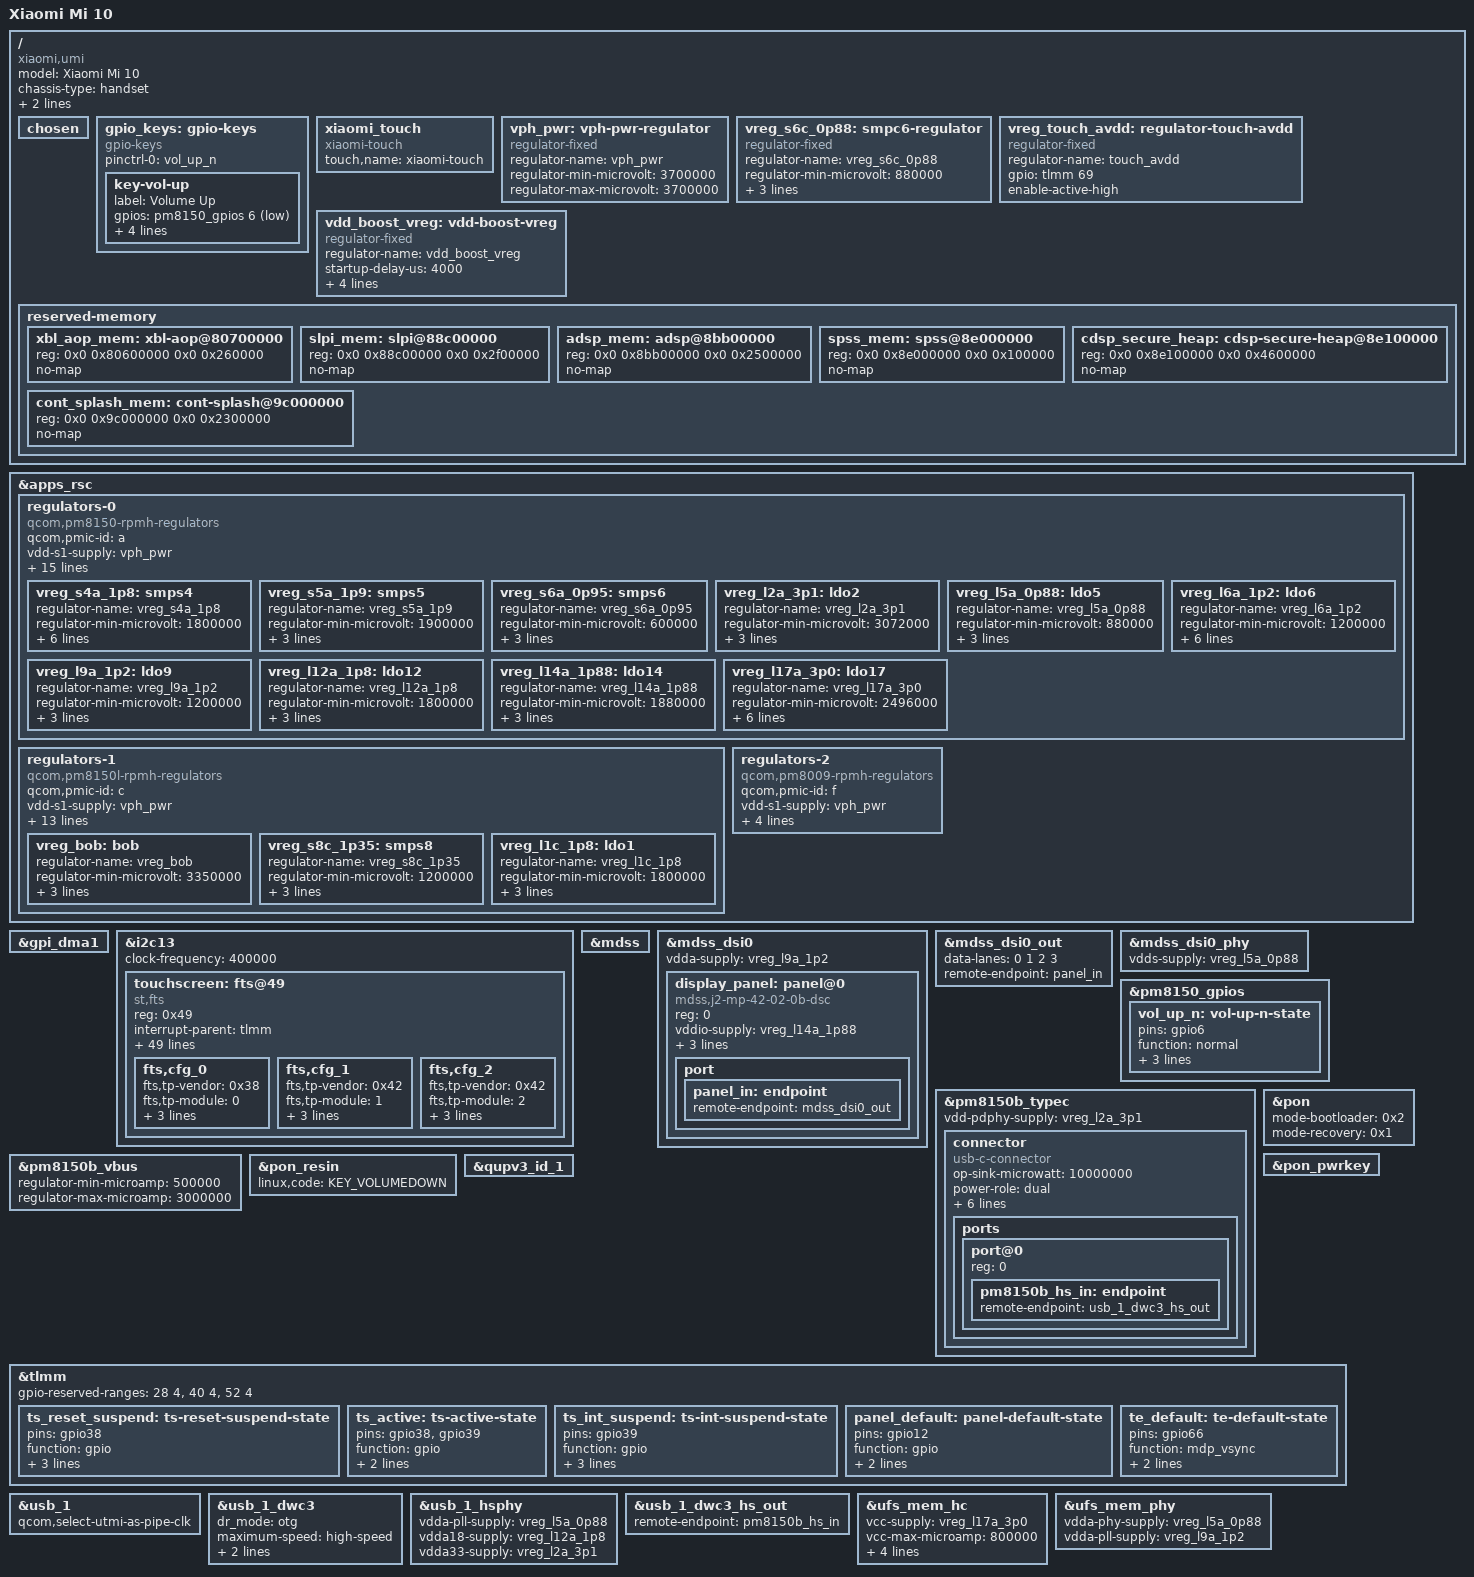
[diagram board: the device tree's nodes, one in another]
// SPDX-License-Identifier: GPL-2.0-only OR BSD-2-Clause
/*
 * Copyright (c) 2025 Xilin Wu <wuxilin123@gmail.com>
 */

/dts-v1/;

#include <dt-bindings/arm/qcom,ids.h>
#include <dt-bindings/phy/phy.h>
#include <dt-bindings/regulator/qcom,rpmh-regulator.h>
#include <dt-bindings/usb/pd.h>
#include "sm8250.dtsi"
#include "pm8150.dtsi"
#include "pm8150b.dtsi"
#include "pm8150l.dtsi"
#include "pm8009.dtsi"

/*
 * Delete following upstream (sm8250.dtsi) reserved
 * memory mappings which are different on this device.
 */
/delete-node/ &adsp_mem;
/delete-node/ &cdsp_secure_heap;
/delete-node/ &slpi_mem;
/delete-node/ &spss_mem;
/delete-node/ &xbl_aop_mem;

/ {

	model = "Xiaomi Mi 10";
	compatible = "xiaomi,umi", "qcom,sm8250";

	chassis-type = "handset";

	/* required for bootloader to select correct board */
	qcom,msm-id = <QCOM_ID_SM8250 0x20001>; /* SM8250 v2.1 */
	qcom,board-id = <0x2b 0>;

	chosen {
		#address-cells = <2>;
		#size-cells = <2>;
		ranges;

		// framebuffer: framebuffer@9c000000 {
		// 	compatible = "simple-framebuffer";
		// 	reg = <0x0 0x9c000000 0x0 0x2300000>;
		// 	width = <1080>;
		// 	height = <2340>;
		// 	stride = <(1080 * 4)>;
		// 	format = "a8r8g8b8";
		// 	clocks = <&gcc GCC_DISP_HF_AXI_CLK>,
		// 		 <&gcc GCC_DISP_SF_AXI_CLK>;
		// };
	};

	gpio_keys: gpio-keys {
		compatible = "gpio-keys";

		pinctrl-0 = <&vol_up_n>;
		pinctrl-names = "default";

		key-vol-up {
			label = "Volume Up";
			gpios = <&pm8150_gpios 6 GPIO_ACTIVE_LOW>;
			linux,code = <KEY_VOLUMEUP>;
			debounce-interval = <15>;
			linux,can-disable;
			wakeup-source;
		};
	};

	xiaomi_touch {
		compatible = "xiaomi-touch";
		touch,name = "xiaomi-touch";
	};

	vph_pwr: vph-pwr-regulator {
		compatible = "regulator-fixed";
		regulator-name = "vph_pwr";
		regulator-min-microvolt = <3700000>;
		regulator-max-microvolt = <3700000>;
	};

	/* S6c is really ebi.lvl but it's there for supply map completeness sake. */
	vreg_s6c_0p88: smpc6-regulator {
		compatible = "regulator-fixed";
		regulator-name = "vreg_s6c_0p88";
		regulator-min-microvolt = <880000>;
		regulator-max-microvolt = <880000>;
		regulator-always-on;
		vin-supply = <&vph_pwr>;
	};

	vreg_touch_avdd: regulator-touch-avdd {
		compatible = "regulator-fixed";
		regulator-name = "touch_avdd";
		gpio = <&tlmm 69 GPIO_ACTIVE_HIGH>;
		// startup-delay-us = <4000>;
		enable-active-high;
		// regulator-boot-on;
	};

	vdd_boost_vreg: vdd-boost-vreg {
		compatible = "regulator-fixed";
		regulator-name = "vdd_boost_vreg";
		startup-delay-us = <4000>;
		enable-active-high;
		regulator-always-on;
		regulator-boot-on;
		gpio = <&pm8150b_gpios 5 0>;
	};

	reserved-memory {
		xbl_aop_mem: xbl-aop@80700000 {
			reg = <0x0 0x80600000 0x0 0x260000>;
			no-map;
		};

		slpi_mem: slpi@88c00000 {
			reg = <0x0 0x88c00000 0x0 0x2f00000>;
			no-map;
		};

		adsp_mem: adsp@8bb00000 {
			reg = <0x0 0x8bb00000 0x0 0x2500000>;
			no-map;
		};

		spss_mem: spss@8e000000 {
			reg = <0x0 0x8e000000 0x0 0x100000>;
			no-map;
		};

		cdsp_secure_heap: cdsp-secure-heap@8e100000 {
			reg = <0x0 0x8e100000 0x0 0x4600000>;
			no-map;
		};

		cont_splash_mem: cont-splash@9c000000 {
			reg = <0x0 0x9c000000 0x0 0x2300000>;
			no-map;
		};

		// ramoops@b0000000 {
		// 	compatible = "ramoops";
		// 	reg = <0x0 0xb0000000 0x0 0x400000>;
		// 	record-size = <0x1000>;
		// 	console-size = <0x200000>;
		// 	ecc-size = <16>;
		// 	no-map;
		// };
	};
};

// &adsp {
// 	firmware-name = "qcom/sm8250/xiaomi/pipa/adsp.mbn";
// 	status = "okay";
// };

&apps_rsc {
	regulators-0 {
		compatible = "qcom,pm8150-rpmh-regulators";
		qcom,pmic-id = "a";

		vdd-s1-supply = <&vph_pwr>;
		vdd-s2-supply = <&vph_pwr>;
		vdd-s3-supply = <&vph_pwr>;
		vdd-s4-supply = <&vph_pwr>;
		vdd-s5-supply = <&vph_pwr>;
		vdd-s6-supply = <&vph_pwr>;
		vdd-s7-supply = <&vph_pwr>;
		vdd-s8-supply = <&vph_pwr>;
		vdd-s9-supply = <&vph_pwr>;
		vdd-s10-supply = <&vph_pwr>;
		vdd-l1-l8-l11-supply = <&vreg_s6c_0p88>;
		vdd-l2-l10-supply = <&vreg_bob>;
		vdd-l3-l4-l5-l18-supply = <&vreg_s6a_0p95>;
		vdd-l6-l9-supply = <&vreg_s8c_1p35>;
		vdd-l7-l12-l14-l15-supply = <&vreg_s5a_1p9>;
		vdd-l13-l16-l17-supply = <&vreg_bob>;

		/* (S1+S2+S3) - cx.lvl (ARC) */

		vreg_s4a_1p8: smps4 {
			regulator-name = "vreg_s4a_1p8";
			regulator-min-microvolt = <1800000>;
			regulator-max-microvolt = <1920000>;
			regulator-initial-mode = <RPMH_REGULATOR_MODE_HPM>;
			regulator-allow-set-load;
			regulator-allowed-modes = <RPMH_REGULATOR_MODE_LPM
						   RPMH_REGULATOR_MODE_HPM>;
		};

		vreg_s5a_1p9: smps5 {
			regulator-name = "vreg_s5a_1p9";
			regulator-min-microvolt = <1900000>;
			regulator-max-microvolt = <2040000>;
			regulator-initial-mode = <RPMH_REGULATOR_MODE_HPM>;
		};

		vreg_s6a_0p95: smps6 {
			regulator-name = "vreg_s6a_0p95";
			regulator-min-microvolt = <600000>;
			regulator-max-microvolt = <1128000>;
			regulator-initial-mode = <RPMH_REGULATOR_MODE_HPM>;
		};

		vreg_l2a_3p1: ldo2 {
			regulator-name = "vreg_l2a_3p1";
			regulator-min-microvolt = <3072000>;
			regulator-max-microvolt = <3072000>;
			regulator-initial-mode = <RPMH_REGULATOR_MODE_HPM>;
		};

		// vreg_l3a_0p9: ldo3 {
		// 	regulator-name = "vreg_l3a_0p9";
		// 	regulator-min-microvolt = <928000>;
		// 	regulator-max-microvolt = <932000>;
		// 	regulator-initial-mode = <RPMH_REGULATOR_MODE_HPM>;
		// };

		/* L4 - lmx.lvl (ARC) */

		vreg_l5a_0p88: ldo5 {
			regulator-name = "vreg_l5a_0p88";
			regulator-min-microvolt = <880000>;
			regulator-max-microvolt = <880000>;
			regulator-initial-mode = <RPMH_REGULATOR_MODE_HPM>;
		};

		vreg_l6a_1p2: ldo6 {
			regulator-name = "vreg_l6a_1p2";
			regulator-min-microvolt = <1200000>;
			regulator-max-microvolt = <1200000>;
			regulator-initial-mode = <RPMH_REGULATOR_MODE_HPM>;
			regulator-allow-set-load;
			regulator-allowed-modes = <RPMH_REGULATOR_MODE_LPM
						   RPMH_REGULATOR_MODE_HPM>;
		};

		/* L7 is unused. */

		vreg_l9a_1p2: ldo9 {
			regulator-name = "vreg_l9a_1p2";
			regulator-min-microvolt = <1200000>;
			regulator-max-microvolt = <1200000>;
			regulator-initial-mode = <RPMH_REGULATOR_MODE_HPM>;
		};

		/* L10 is unused, L11 - lcx.lvl (ARC) */

		vreg_l12a_1p8: ldo12 {
			regulator-name = "vreg_l12a_1p8";
			regulator-min-microvolt = <1800000>;
			regulator-max-microvolt = <1800000>;
			regulator-initial-mode = <RPMH_REGULATOR_MODE_HPM>;
		};

		/* L13 is unused. */

		vreg_l14a_1p88: ldo14 {
			regulator-name = "vreg_l14a_1p88";
			regulator-min-microvolt = <1880000>;
			regulator-max-microvolt = <1880000>;
			regulator-initial-mode = <RPMH_REGULATOR_MODE_HPM>;
		};

		/* L15 & L16 are unused. */

		vreg_l17a_3p0: ldo17 {
			regulator-name = "vreg_l17a_3p0";
			regulator-min-microvolt = <2496000>;
			regulator-max-microvolt = <3008000>;
			regulator-initial-mode = <RPMH_REGULATOR_MODE_HPM>;
			regulator-allow-set-load;
			regulator-allowed-modes = <RPMH_REGULATOR_MODE_LPM
						   RPMH_REGULATOR_MODE_HPM>;
		};

		// vreg_l18a_0p9: ldo18 {
		// 	regulator-name = "vreg_l18a_0p9";
		// 	regulator-min-microvolt = <800000>;
		// 	regulator-max-microvolt = <920000>;
		// 	regulator-initial-mode = <RPMH_REGULATOR_MODE_HPM>;
		// };
	};

	regulators-1 {
		compatible = "qcom,pm8150l-rpmh-regulators";
		qcom,pmic-id = "c";

		vdd-s1-supply = <&vph_pwr>;
		vdd-s2-supply = <&vph_pwr>;
		vdd-s3-supply = <&vph_pwr>;
		vdd-s4-supply = <&vph_pwr>;
		vdd-s5-supply = <&vph_pwr>;
		vdd-s6-supply = <&vph_pwr>;
		vdd-s7-supply = <&vph_pwr>;
		vdd-s8-supply = <&vph_pwr>;
		vdd-l1-l8-supply = <&vreg_s4a_1p8>;
		vdd-l2-l3-supply = <&vreg_s8c_1p35>;
		vdd-l4-l5-l6-supply = <&vreg_bob>;
		vdd-l7-l11-supply = <&vreg_bob>;
		vdd-l9-l10-supply = <&vreg_bob>;
		vdd-bob-supply = <&vph_pwr>;

		vreg_bob: bob {
			regulator-name = "vreg_bob";
			regulator-min-microvolt = <3350000>;
			regulator-max-microvolt = <3960000>;
			regulator-initial-mode = <RPMH_REGULATOR_MODE_AUTO>;
		};

		/*
		 * S1-S6 are ARCs:
		 * (S1+S2) - gfx.lvl,
		 * S3 - mx.lvl,
		 * (S4+S5) - mmcx.lvl,
		 * S6 - ebi.lvl
		 */

		// vreg_s7c_0p35: smps7 {
		// 	regulator-name = "vreg_s7c_0p35";
		// 	regulator-min-microvolt = <348000>;
		// 	regulator-max-microvolt = <1000000>;
		// 	regulator-initial-mode = <RPMH_REGULATOR_MODE_HPM>;
		// };

		vreg_s8c_1p35: smps8 {
			regulator-name = "vreg_s8c_1p35";
			regulator-min-microvolt = <1200000>;
			regulator-max-microvolt = <1400000>;
			regulator-initial-mode = <RPMH_REGULATOR_MODE_HPM>;
		};

		vreg_l1c_1p8: ldo1 {
			regulator-name = "vreg_l1c_1p8";
			regulator-min-microvolt = <1800000>;
			regulator-max-microvolt = <1800000>;
			regulator-initial-mode = <RPMH_REGULATOR_MODE_HPM>;
		};

		/* L2-4 are unused. */

		// vreg_l5c_1p8: ldo5 {
		// 	regulator-name = "vreg_l5c_1p8";
		// 	regulator-min-microvolt = <1800000>;
		// 	regulator-max-microvolt = <2800000>;
		// 	regulator-initial-mode = <RPMH_REGULATOR_MODE_HPM>;
		// };

		// vreg_l6c_2p9: ldo6 {
		// 	regulator-name = "vreg_l6c_2p9";
		// 	regulator-min-microvolt = <1800000>;
		// 	regulator-max-microvolt = <2960000>;
		// 	regulator-initial-mode = <RPMH_REGULATOR_MODE_HPM>;
		// 	regulator-allow-set-load;
		// 	regulator-allowed-modes = <RPMH_REGULATOR_MODE_LPM
		// 				   RPMH_REGULATOR_MODE_HPM>;
		// };

		// vreg_l7c_2p85: ldo7 {
		// 	regulator-name = "vreg_l7c_2p85";
		// 	regulator-min-microvolt = <2856000>;
		// 	regulator-max-microvolt = <3104000>;
		// 	regulator-initial-mode = <RPMH_REGULATOR_MODE_HPM>;
		// };

		// vreg_l8c_1p8: ldo8 {
		// 	regulator-name = "vreg_l8c_1p8";
		// 	regulator-min-microvolt = <1800000>;
		// 	regulator-max-microvolt = <1800000>;
		// 	regulator-initial-mode = <RPMH_REGULATOR_MODE_HPM>;
		// };

		// vreg_l9c_2p9: ldo9 {
		// 	regulator-name = "vreg_l9c_2p9";
		// 	regulator-min-microvolt = <2704000>;
		// 	regulator-max-microvolt = <2960000>;
		// 	regulator-initial-mode = <RPMH_REGULATOR_MODE_HPM>;
		// 	regulator-allow-set-load;
		// 	regulator-allowed-modes = <RPMH_REGULATOR_MODE_LPM
		// 				   RPMH_REGULATOR_MODE_HPM>;
		// };

		// vreg_l10c_3p3: ldo10 {
		// 	regulator-name = "vreg_l10c_3p3";
		// 	regulator-min-microvolt = <3000000>;
		// 	regulator-max-microvolt = <3312000>;
		// 	regulator-initial-mode = <RPMH_REGULATOR_MODE_HPM>;
		// };

		// vreg_l11c_3p0: ldo11 {
		// 	regulator-name = "vreg_l11c_3p0";
		// 	regulator-min-microvolt = <3104000>;
		// 	regulator-max-microvolt = <3304000>;
		// 	regulator-initial-mode = <RPMH_REGULATOR_MODE_HPM>;
		// };
	};

	regulators-2 {
		compatible = "qcom,pm8009-rpmh-regulators";
		qcom,pmic-id = "f";

		vdd-s1-supply = <&vph_pwr>;
		vdd-s2-supply = <&vreg_bob>;
		vdd-l2-supply = <&vreg_s8c_1p35>;
		vdd-l5-l6-supply = <&vreg_bob>;
		vdd-l7-supply = <&vreg_s4a_1p8>;

		// vreg_s1f_1p2: smps1 {
		// 	regulator-name = "vreg_s1f_1p2";
		// 	regulator-min-microvolt = <1200000>;
		// 	regulator-max-microvolt = <1300000>;
		// 	regulator-initial-mode = <RPMH_REGULATOR_MODE_HPM>;
		// };

		// vreg_s2f_0p5: smps2 {
		// 	regulator-name = "vreg_s2f_0p5";
		// 	regulator-min-microvolt = <512000>;
		// 	regulator-max-microvolt = <1100000>;
		// 	regulator-initial-mode = <RPMH_REGULATOR_MODE_HPM>;
		// };

		/* L1 is unused. */

		// vreg_l2f_1p3: ldo2 {
		// 	regulator-name = "vreg_l2f_1p3";
		// 	regulator-min-microvolt = <1056000>;
		// 	regulator-max-microvolt = <1200000>;
		// 	regulator-initial-mode = <RPMH_REGULATOR_MODE_HPM>;
		// };

		/* L3 & L4 are unused. */

		// vreg_l5f_2p8: ldo5 {
		// 	regulator-name = "vreg_l5f_2p85";
		// 	regulator-min-microvolt = <2800000>;
		// 	regulator-max-microvolt = <3000000>;
		// 	regulator-initial-mode = <RPMH_REGULATOR_MODE_HPM>;
		// };

		// vreg_l6f_2p8: ldo6 {
		// 	regulator-name = "vreg_l6f_2p8";
		// 	regulator-min-microvolt = <2800000>;
		// 	regulator-max-microvolt = <3000000>;
		// 	regulator-initial-mode = <RPMH_REGULATOR_MODE_HPM>;
		// };

		// vreg_l7f_1p8: ldo7 {
		// 	regulator-name = "vreg_l7f_1p8";
		// 	regulator-min-microvolt = <1800000>;
		// 	regulator-max-microvolt = <1800000>;
		// 	regulator-initial-mode = <RPMH_REGULATOR_MODE_HPM>;
		// };
	};
};

// &cdsp {
// 	firmware-name = "qcom/sm8250/xiaomi/pipa/cdsp.mbn";
// 	status = "okay";
// };

// &dispcc {
//     status = "disabled";
// };

// &gmu {
// 	status = "okay";
// };

// &gpi_dma0 {
// 	status = "okay";
// };

&gpi_dma1 {
	status = "okay";
};

// &gpi_dma2 {
// 	status = "okay";
// };

// &gpu {
// 	status = "okay";

// 	zap-shader {
// 		memory-region = <&gpu_mem>;
// 		firmware-name = "qcom/sm8250/xiaomi/pipa/a650_zap.mbn";
// 	};
// };

// &i2c0 {
// 	clock-frequency = <400000>;
// 	status = "okay";
// };

// &i2c11 {
// 	clock-frequency = <400000>;
// 	status = "okay";
// };

&i2c13 {
	clock-frequency = <400000>;
	status = "okay";

	// touchscreen: fts@49 {
	// 	compatible = "st,fts";
	// 	reg = <0x49>;

	// 	interrupt-parent = <&tlmm>;
	// 	interrupts = <39 IRQ_TYPE_LEVEL_LOW>;

	// 	pinctrl-0 = <&ts_active>;
	// 	pinctrl-1 = <&ts_int_suspend &ts_reset_suspend>;
	// 	pinctrl-names = "default", "sleep";

	// 	vdd-supply = <&vreg_l1c_1p8>;
	// 	avdd-supply = <&vreg_touch_avdd>;
	// 	fts,regulator_dvdd = "vdd";
	// 	fts,regulator_avdd = "avdd";

	// 	fts,irq-gpio = <&tlmm 39 GPIO_TRANSITORY>;
	// 	fts,irq-flags = <0x2008>; /* oneshot and trigger low */

	// 	fts,reset-gpio-enable;
	// 	fts,reset-gpio = <&tlmm 38 GPIO_ACTIVE_HIGH>;

	// 	fts,x-max = <1080>;
	// 	fts,y-max = <2340>;
	// };

	touchscreen: fts@49 {
		status = "ok";
		compatible = "st,fts";
		reg = <0x49>;
		interrupt-parent = <&tlmm>;
		interrupts = <39 0x2008>;
		pinctrl-names = "pmx_ts_active", "pmx_ts_suspend";
		pinctrl-0 = <&ts_active>;
		pinctrl-1 = <&ts_int_suspend &ts_reset_suspend>;
		avdd-supply = <&vreg_touch_avdd>;
		vdd-supply = <&vreg_l1c_1p8>;
		fts,pwr-reg-name = "avdd";
		fts,bus-reg-name = "vdd";
		fts,irq-gpio = <&tlmm 39 0x2008>;
		fts,irq-gpio-name = "fts_irq";
		fts,reset-gpio-enable;
		fts,reset-gpio = <&tlmm 38 0x00>;
		fts,reset-gpio-name = "fts_rst";
		fts,irq-flags = <0x2008>; /* IRQF_ONESHOT | IRQF_TRIGGER_LOW */
		fts,x-max = <1080>;
		fts,y-max = <2340>;
		fts,fod-lx = <421>;
		fts,fod-ly = <1788>;
		fts,fod-x-size = <238>;
		fts,fod-y-size = <238>;
		fts,default-fw-name = "st_fts_j2.ftb";
		fts,config-array-size = <3>;
		fts,dump-click-count;
		fts,support-fod;
		fts,touch-up-threshold-min = <40>;
		fts,touch-up-threshold-max = <120>;
		fts,touch-up-threshold-def = <80>;
		fts,touch-tolerance-min = <5>;
		fts,touch-tolerance-max = <35>;
		fts,touch-tolerance-def = <25>;
		fts,touch-idletime-min = <0>;
		fts,touch-idletime-max = <12750>;
		fts,touch-idletime-def = <12450>;
		/*edge filter rects in gamemode*/
		fts,cornerfilter-area-step1 = <100>;
		fts,cornerfilter-area-step2 = <170>;
		fts,cornerfilter-area-step3 = <250>;
		fts,touch-deadzone-filter-ver = <2 0 0 0 0 0 0 0
										2 1 0 0 0 0 0 0
										2 2 0 0 5 2339 0 0
										2 3 1074 0 1079 2339 0 0>;
		fts,touch-deadzone-filter-hor = <2 0 0 0 1079 5 0 0
										2 1 0 2334 1079 2339 0 0
										2 2 0 0 5 2339 0 0
										2 3 1074 0 1079 2339 0 0>;
		fts,touch-edgezone-filter-ver = <1 0 0 0 0 0 0 0
										1 1 0 0 0 0 0 0
										1 2 0 0 40 2339 0 0
										1 3 1039 0 1079 2339 0 0>;
		fts,touch-edgezone-filter-hor = <1 0 0 0 1079 40 0 0
										1 1 0 2299 1079 2339 0 0
										1 2 0 0 40 2339 0 0
										1 3 1039 0 1079 2339 0 0>;
		fts,touch-cornerzone-filter-ver = <0 0 0 0 0 0 0 0
										0 1 0 0 0 0 0 0
										0 2 0 2039 150 2339 0 0
										0 3 929 2039 1079 2339 0 0>;
		fts,touch-cornerzone-filter-hor1 = <0 0 0 0 170 170 0 0
										0 1 0 0 0 0 0 0
										0 2 0 2169 170 2339 0 0
										0 3 0 0 0 0 0 0>;
		fts,touch-cornerzone-filter-hor2 = <0 0 0 0 0 0 0 0
										0 1 909 0 1079 170 0 0
										0 2 0 0 0 0 0 0
										0 3 909 2169 1079 2339 0 0>;
		fts,cfg_0 {
			fts,tp-vendor = <0x38>;
			fts,tp-module = <0>;
			fts,fw-name = "st_fts_j2_1.ftb";
			fts,limit-name = "stm_fts_production_limits_1.csv";
		};
		fts,cfg_1 {
			fts,tp-vendor = <0x42>;
			fts,tp-module = <1>;
			fts,fw-name = "st_fts_j2_2.ftb";
			fts,limit-name = "stm_fts_production_limits_2.csv";
		};
		fts,cfg_2{
			fts,tp-vendor = <0x42>;
			fts,tp-module = <2>;
			fts,fw-name = "st_fts_j2_3.ftb";
			fts,limit-name = "stm_fts_production_limits_2.csv";
		};
	};
};

&mdss {
	status = "okay";
};

&mdss_dsi0 {
	vdda-supply = <&vreg_l9a_1p2>;
	// qcom,dual-dsi-mode;
	// qcom,sync-dual-dsi;
	// qcom,master-dsi;
	status = "okay";

	display_panel: panel@0 {
		compatible = "mdss,j2-mp-42-02-0b-dsc";
		reg = <0>;
		vddio-supply = <&vreg_l14a_1p88>;
		reset-gpios = <&tlmm 12 GPIO_ACTIVE_LOW>;
		disprate-gpios = <&tlmm 50 GPIO_ACTIVE_HIGH>;
		// backlight = <&backlight>;
		// rotation = <90>;

		pinctrl-names = "default";
		pinctrl-0 = <&panel_default>, <&te_default>;


		// status = "disabled";

		port {
			panel_in: endpoint {
				remote-endpoint = <&mdss_dsi0_out>;
			};
		};
	};
};

&mdss_dsi0_out {
	data-lanes = <0 1 2 3>;
	remote-endpoint = <&panel_in>;
};

&mdss_dsi0_phy {
	vdds-supply = <&vreg_l5a_0p88>;
	// phy-type = <PHY_TYPE_CPHY>;
	status = "okay";
};

// &pcie0 {
// 	status = "okay";
// };

// &pcie0_phy {
// 	vdda-phy-supply = <&vreg_l5a_0p88>;
// 	vdda-pll-supply = <&vreg_l9a_1p2>;
// 	status = "okay";
// };

&pm8150_gpios {
	vol_up_n: vol-up-n-state {
		pins = "gpio6";
		function = "normal";
		power-source = <1>;
		input-enable;
		bias-pull-up;
	};
};

&pm8150b_typec {
	vdd-pdphy-supply = <&vreg_l2a_3p1>;
	status = "okay";

	connector {
		compatible = "usb-c-connector";

		op-sink-microwatt = <10000000>;
		power-role = "dual";
		data-role = "dual";
		self-powered;

		source-pdos = <PDO_FIXED(5000, 3000,
					 PDO_FIXED_DUAL_ROLE |
					 PDO_FIXED_USB_COMM |
					 PDO_FIXED_DATA_SWAP)>;

		sink-pdos = <PDO_FIXED(5000, 3000,
				       PDO_FIXED_DUAL_ROLE |
				       PDO_FIXED_USB_COMM |
				       PDO_FIXED_DATA_SWAP)
				       PDO_VAR(5000, 12000, 5000)>;

		ports {
			#address-cells = <1>;
			#size-cells = <0>;

			port@0 {
				reg = <0>;

				pm8150b_hs_in: endpoint {
					remote-endpoint = <&usb_1_dwc3_hs_out>;
				};
			};
		};
	};
};

&pm8150b_vbus {
	regulator-min-microamp = <500000>;
	regulator-max-microamp = <3000000>;
	status = "okay";
};

&pon {
	mode-bootloader = <0x2>;
	mode-recovery = <0x1>;
};

&pon_pwrkey {
	status = "okay";
};

&pon_resin {
	linux,code = <KEY_VOLUMEDOWN>;
	status = "okay";
};

// &qupv3_id_0 {
// 	status = "okay";
// };

&qupv3_id_1 {
	status = "okay";
};

// &qupv3_id_2 {
// 	status = "okay";
// };

// &slpi {
// 	firmware-name = "qcom/sm8250/xiaomi/pipa/slpi.mbn";
// 	status = "okay";
// };

&tlmm {
	gpio-reserved-ranges = <28 4>, <40 4>, <52 4>;

	// ts_reset_active: ts-reset-active-state {
	// 	pins = "gpio38";
	// 	function = "gpio";
	// 	drive-strength = <16>;
	// 	bias-pull-up;
	// };

	ts_reset_suspend: ts-reset-suspend-state {
		pins = "gpio38";
		function = "gpio";
		drive-strength = <16>;
		bias-disable;
		output-high;
	};

	ts_active: ts-active-state {
		pins = "gpio38", "gpio39";
		function = "gpio";
		drive-strength = <16>;
		bias-pull-up;
	};

	ts_int_suspend: ts-int-suspend-state {
		pins = "gpio39";
		function = "gpio";
		drive-strength = <16>;
		input-enable;
		bias-disable;
	};

	panel_default: panel-default-state {
		pins = "gpio12";
		function = "gpio";
		drive-strength = <8>;
		bias-disable;
	};

	te_default: te-default-state {
		pins = "gpio66";
		function = "mdp_vsync";
		drive-strength = <2>;
		bias-pull-down;
	};
};

&usb_1 {
	/* USB 2.0 only */
	qcom,select-utmi-as-pipe-clk;
	status = "okay";
};

&usb_1_dwc3 {
	dr_mode = "otg";
	maximum-speed = "high-speed";
	/* Remove USB3 phy */
	phys = <&usb_1_hsphy>;
	phy-names = "usb2-phy";
	usb-role-switch;
};

&usb_1_hsphy {
	vdda-pll-supply = <&vreg_l5a_0p88>;
	vdda18-supply = <&vreg_l12a_1p8>;
	vdda33-supply = <&vreg_l2a_3p1>;
	status = "okay";
};

&usb_1_dwc3_hs_out {
	remote-endpoint = <&pm8150b_hs_in>;
};

&ufs_mem_hc {
	vcc-supply = <&vreg_l17a_3p0>;
	vcc-max-microamp = <800000>;
	vccq-supply = <&vreg_l6a_1p2>;
	vccq-max-microamp = <800000>;
	vccq2-supply = <&vreg_s4a_1p8>;
	vccq2-max-microamp = <800000>;
	status = "okay";
};

&ufs_mem_phy {
	vdda-phy-supply = <&vreg_l5a_0p88>;
	vdda-pll-supply = <&vreg_l9a_1p2>;
	status = "okay";
};

// &venus {
// 	firmware-name = "qcom/sm8250/xiaomi/pipa/venus.mbn";
// 	status = "okay";
// };
